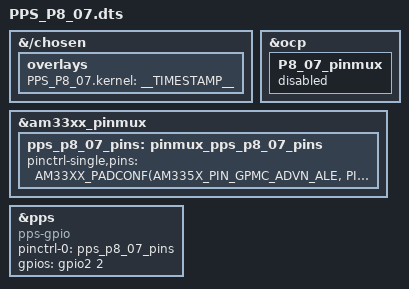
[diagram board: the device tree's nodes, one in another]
/dts-v1/;
/plugin/;

#include <dt-bindings/pinctrl/am33xx.h>

&{/chosen} {
	overlays {
		PPS_P8_07.kernel = __TIMESTAMP__;
	};
};

&ocp {
  P8_07_pinmux { status="disabled"; }; /* P8_07: timer4 */
};


&am33xx_pinmux {
  pps_p8_07_pins: pinmux_pps_p8_07_pins {
    pinctrl-single,pins = <
     AM33XX_PADCONF(AM335X_PIN_GPMC_ADVN_ALE, PIN_INPUT, MUX_MODE0) 
    >;
  };
};

&pps {
    status = "okay";
    compatible="pps-gpio";
    pinctrl-names = "default";
    pinctrl-0 = <&pps_p8_07_pins>;
    gpios = <&gpio2 2 0>;
};

